# timer32 register map
Vendor: Texas Instruments
Peripheral module from a debugger description file (folder MSP432).
Registers are 32-bit, read-write, no defined reset value unless marked. A register's access mark holds for its fields unless they carry their own. Offsets are as the file gives them; lines under a group give offsets from that group; [hi:lo] are bit positions; {n}, {i} and the like mark numbered series; 'fields as' and 'values as' point back to an identical list; <NAME> marks a mode.

## Timer32
0x00 LOAD1 — Timer 1 Load Register
  [31:0] LOAD — The value from which the Timer 1 counter decrements
0x04 VALUE1 access not given — Timer 1 Current Value Register
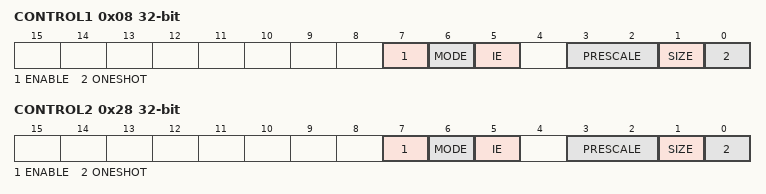
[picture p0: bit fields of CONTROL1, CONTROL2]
0x08 CONTROL1 — Timer 1 Timer Control Register
  [7] ENABLE — Enable bit
    0=ENABLE__0 (Timer disabled); 1=ENABLE__1 (Timer enabled)
  [6] MODE — Mode bit
    0=MODE__0 (Timer is in free-running mode); 1=MODE__1 (Timer is in periodic mode)
  [5] IE — Interrupt enable bit
    0=IE__0 (Timer interrupt disabled); 1=IE__1 (Timer interrupt enabled)
  [3:2] PRESCALE — Prescale bits
    0=PRESCALE__0 (0 stages of prescale, clock is divided by 1); 1=PRESCALE__1 (4 stages of prescale, clock is divided by 16); 2=PRESCALE__2 (8 stages of prescale, clock is divided by 256)
  [1] SIZE — Selects 16 or 32 bit counter operation
    0=SIZE__0 (16-bit counter); 1=SIZE__1 (32-bit counter)
  [0] ONESHOT — Selects one-shot or wrapping counter mode
    0=ONESHOT__0 (wrapping mode); 1=ONESHOT__1 (one-shot mode)
0x0C INTCLR1 — Timer 1 Interrupt Clear Register
  [31:0] INTCLR — Any write to the T32INTCLR1 register clears the interrupt
0x10 RIS1 — Timer 1 Raw Interrupt Status Register
  [0] RAW_IFG — Raw interrupt status from the counter
0x14 MIS1 access not given — Timer 1 Interrupt Status Register
0x18 BGLOAD1 — Timer 1 Background Load Register
  [31:0] BGLOAD — Contains the value from which the counter decrements
0x20 LOAD2 — Timer 2 Load Register
  [31:0] LOAD — The value from which the Timer 2 counter decrements
0x24 VALUE2 — Timer 2 Current Value Register
  [31:0] VALUE — Reports the current value of the decrementing counter
0x28 CONTROL2 — Timer 2 Timer Control Register
  fields as CONTROL1
0x2C INTCLR2 — Timer 2 Interrupt Clear Register
  [31:0] INTCLR — Any write to the T32INTCLR2 register clears the interrupt outpu
0x30 RIS2 — Timer 2 Raw Interrupt Status Register
  [0] RAW_IFG — Raw interrupt status from the counter
0x34 MIS2 — Timer 2 Interrupt Status Register
  [0] IFG — Enabled interrupt status from the counter
0x38 BGLOAD2 — Timer 2 Background Load Register
  [31:0] BGLOAD — Contains the value from which the counter decrements
